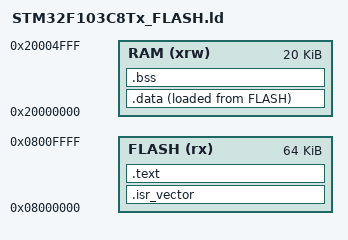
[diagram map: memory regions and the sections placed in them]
/* Very minimal linker script for STM32F103C8Tx (64kB flash, 20kB RAM) */

MEMORY
{
  FLASH (rx) : ORIGIN = 0x08000000, LENGTH = 64K
  RAM   (xrw) : ORIGIN = 0x20000000, LENGTH = 20K
}

SECTIONS
{
  .isr_vector :
  {
    . = ALIGN(4);
    KEEP(*(.isr_vector))
    . = ALIGN(4);
  } > FLASH

  .text :
  {
    . = ALIGN(4);
    *(.text*)
    *(.rodata*)
    . = ALIGN(4);
  } > FLASH

  .data :
  {
    . = ALIGN(4);
    _sdata = .;
    *(.data*)
    . = ALIGN(4);
    _edata = .;
  } > RAM AT > FLASH

  .bss :
  {
    . = ALIGN(4);
    _sbss = .;
    *(.bss*)
    *(COMMON)
    . = ALIGN(4);
    _ebss = .;
  } > RAM

  /* Stack at the end of RAM */
  _estack = ORIGIN(RAM) + LENGTH(RAM);
}
